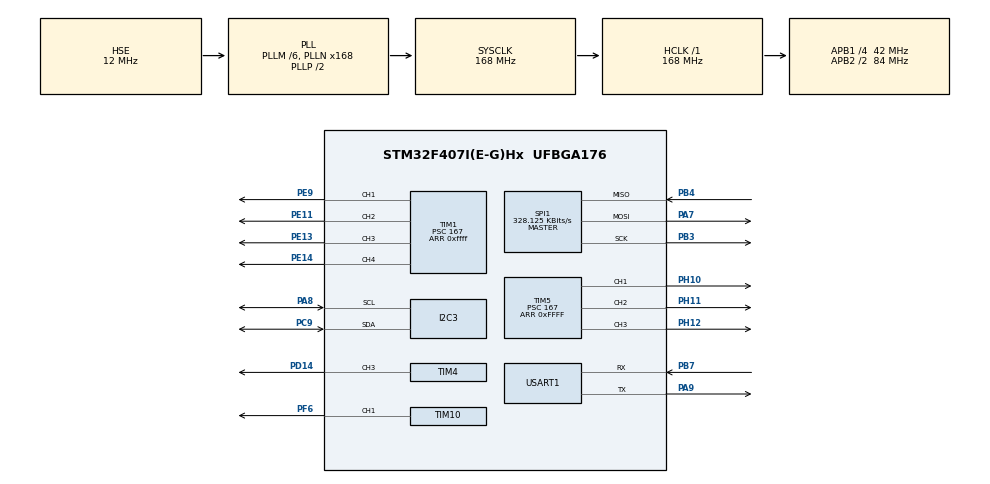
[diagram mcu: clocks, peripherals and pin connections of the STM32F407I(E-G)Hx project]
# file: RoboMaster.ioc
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Dma.Request0=USART1_TX
Dma.Request1=USART1_RX
Dma.Request2=SPI1_TX
Dma.Request3=SPI1_RX
Dma.SPI1_RX.3.Direction=DMA_PERIPH_TO_MEMORY
Dma.SPI1_RX.3.FIFOMode=DMA_FIFOMODE_DISABLE
Dma.SPI1_RX.3.Instance=DMA2_Stream0
Dma.SPI1_RX.3.MemDataAlignment=DMA_MDATAALIGN_BYTE
Dma.SPI1_RX.3.MemInc=DMA_MINC_ENABLE
Dma.SPI1_RX.3.Mode=DMA_NORMAL
Dma.SPI1_RX.3.PeriphDataAlignment=DMA_PDATAALIGN_BYTE
Dma.SPI1_RX.3.PeriphInc=DMA_PINC_DISABLE
Dma.SPI1_RX.3.Priority=DMA_PRIORITY_VERY_HIGH
Dma.SPI1_TX.2.Direction=DMA_MEMORY_TO_PERIPH
Dma.SPI1_TX.2.FIFOMode=DMA_FIFOMODE_DISABLE
Dma.SPI1_TX.2.Instance=DMA2_Stream3
Dma.SPI1_TX.2.MemDataAlignment=DMA_MDATAALIGN_BYTE
Dma.SPI1_TX.2.MemInc=DMA_MINC_ENABLE
Dma.SPI1_TX.2.Mode=DMA_NORMAL
Dma.SPI1_TX.2.PeriphDataAlignment=DMA_PDATAALIGN_BYTE
Dma.SPI1_TX.2.PeriphInc=DMA_PINC_DISABLE
Dma.SPI1_TX.2.Priority=DMA_PRIORITY_HIGH
Dma.USART1_RX.1.Direction=DMA_PERIPH_TO_MEMORY
Dma.USART1_RX.1.FIFOMode=DMA_FIFOMODE_DISABLE
Dma.USART1_RX.1.Instance=DMA2_Stream2
Dma.USART1_RX.1.MemDataAlignment=DMA_MDATAALIGN_BYTE
Dma.USART1_RX.1.MemInc=DMA_MINC_ENABLE
Dma.USART1_RX.1.Mode=DMA_NORMAL
Dma.USART1_RX.1.PeriphDataAlignment=DMA_PDATAALIGN_BYTE
Dma.USART1_RX.1.PeriphInc=DMA_PINC_DISABLE
Dma.USART1_RX.1.Priority=DMA_PRIORITY_MEDIUM
Dma.USART1_TX.0.Direction=DMA_MEMORY_TO_PERIPH
Dma.USART1_TX.0.FIFOMode=DMA_FIFOMODE_DISABLE
Dma.USART1_TX.0.Instance=DMA2_Stream7
Dma.USART1_TX.0.MemDataAlignment=DMA_MDATAALIGN_BYTE
Dma.USART1_TX.0.MemInc=DMA_MINC_ENABLE
Dma.USART1_TX.0.Mode=DMA_NORMAL
Dma.USART1_TX.0.PeriphDataAlignment=DMA_PDATAALIGN_BYTE
Dma.USART1_TX.0.PeriphInc=DMA_PINC_DISABLE
Dma.USART1_TX.0.Priority=DMA_PRIORITY_MEDIUM
FREERTOS.Tasks01=defaultTask,0,128,StartDefaultTask,Default,NULL,Dynamic,NULL,NULL
I2C3.I2C_Mode=I2C_Fast
Mcu.Family=STM32F4
Mcu.Name=STM32F407I(E-G)Hx
Mcu.Package=UFBGA176
NVIC.DMA2_Stream0_IRQn=true\:5\:0\:false\:false\:true\:true\:false\:true
NVIC.DMA2_Stream2_IRQn=true\:5\:0\:false\:false\:true\:true\:false\:true
NVIC.DMA2_Stream3_IRQn=true\:5\:0\:false\:false\:true\:true\:false\:true
NVIC.DMA2_Stream7_IRQn=true\:5\:0\:false\:false\:true\:true\:false\:true
NVIC.PriorityGroup=NVIC_PRIORITYGROUP_4
NVIC.USART1_IRQn=true\:5\:0\:false\:false\:true\:true\:true\:true
PA7.GPIO_PuPd=GPIO_PULLUP
PA7.Mode=Full_Duplex_Master
PA7.Signal=SPI1_MOSI
PA8.Mode=I2C
PA8.Signal=I2C3_SCL
PA9.Mode=Asynchronous
PA9.Signal=USART1_TX
PB3.GPIO_PuPd=GPIO_PULLUP
PB3.Mode=Full_Duplex_Master
PB3.Signal=SPI1_SCK
PB4.GPIO_PuPd=GPIO_PULLUP
PB4.Mode=Full_Duplex_Master
PB4.Signal=SPI1_MISO
PB7.Mode=Asynchronous
PB7.Signal=USART1_RX
PC9.Mode=I2C
PC9.Signal=I2C3_SDA
PD14.GPIO_PuPd=GPIO_PULLDOWN
PD14.Signal=S_TIM4_CH3
PE11.GPIO_PuPd=GPIO_PULLDOWN
PE11.Signal=S_TIM1_CH2
PE13.GPIO_PuPd=GPIO_PULLDOWN
PE13.Signal=S_TIM1_CH3
PE14.GPIO_PuPd=GPIO_PULLDOWN
PE14.Signal=S_TIM1_CH4
PE9.GPIO_PuPd=GPIO_PULLDOWN
PE9.Signal=S_TIM1_CH1
PF6.GPIO_PuPd=GPIO_PULLUP
PF6.GPIO_Speed=GPIO_SPEED_FREQ_HIGH
PF6.Signal=S_TIM10_CH1
PH0-OSC_IN.Mode=HSE-External-Oscillator
PH0-OSC_IN.Signal=RCC_OSC_IN
PH1-OSC_OUT.Mode=HSE-External-Oscillator
PH1-OSC_OUT.Signal=RCC_OSC_OUT
PH10.GPIO_PuPd=GPIO_PULLDOWN
PH10.GPIO_Speed=GPIO_SPEED_FREQ_MEDIUM
PH10.Signal=S_TIM5_CH1
PH11.GPIO_PuPd=GPIO_PULLDOWN
PH11.GPIO_Speed=GPIO_SPEED_FREQ_MEDIUM
PH11.Signal=S_TIM5_CH2
PH12.GPIO_PuPd=GPIO_PULLDOWN
PH12.GPIO_Speed=GPIO_SPEED_FREQ_MEDIUM
PH12.Signal=S_TIM5_CH3
ProjectManager.HeapSize=0x200
ProjectManager.StackSize=0x400
ProjectManager.TargetToolchain=Makefile
RCC.48MHZClocksFreq_Value=84000000
RCC.AHBFreq_Value=168000000
RCC.APB1CLKDivider=RCC_HCLK_DIV4
RCC.APB1Freq_Value=42000000
RCC.APB1TimFreq_Value=84000000
RCC.APB2CLKDivider=RCC_HCLK_DIV2
RCC.APB2Freq_Value=84000000
RCC.APB2TimFreq_Value=168000000
RCC.CortexFreq_Value=168000000
RCC.HCLKFreq_Value=168000000
RCC.HSE_VALUE=12000000
RCC.HSI_VALUE=16000000
RCC.LSE_VALUE=32768
RCC.PLLM=6
RCC.PLLN=168
RCC.PLLSourceVirtual=RCC_PLLSOURCE_HSE
RCC.SYSCLKFreq_VALUE=168000000
RCC.SYSCLKSource=RCC_SYSCLKSOURCE_PLLCLK
RCC.VCOOutputFreq_Value=336000000
SH.S_TIM10_CH1.0=TIM10_CH1,PWM Generation1 CH1
SH.S_TIM1_CH1.0=TIM1_CH1,PWM Generation1 CH1
SH.S_TIM1_CH2.0=TIM1_CH2,PWM Generation2 CH2
SH.S_TIM1_CH3.0=TIM1_CH3,PWM Generation3 CH3
SH.S_TIM1_CH4.0=TIM1_CH4,PWM Generation4 CH4
SH.S_TIM4_CH3.0=TIM4_CH3,PWM Generation3 CH3
SH.S_TIM5_CH1.0=TIM5_CH1,PWM Generation1 CH1
SH.S_TIM5_CH2.0=TIM5_CH2,PWM Generation2 CH2
SH.S_TIM5_CH3.0=TIM5_CH3,PWM Generation3 CH3
SPI1.BaudRatePrescaler=SPI_BAUDRATEPRESCALER_256
SPI1.CLKPolarity=SPI_POLARITY_HIGH
SPI1.CalculateBaudRate=328.125 KBits/s
SPI1.Direction=SPI_DIRECTION_2LINES
SPI1.Mode=SPI_MODE_MASTER
SPI1.VirtualType=VM_MASTER
TIM1.Channel-PWM\ Generation1\ CH1=TIM_CHANNEL_1
TIM1.Channel-PWM\ Generation2\ CH2=TIM_CHANNEL_2
TIM1.Channel-PWM\ Generation3\ CH3=TIM_CHANNEL_3
TIM1.Channel-PWM\ Generation4\ CH4=TIM_CHANNEL_4
TIM1.Period=0xffff
TIM1.Prescaler=167
TIM10.Channel=TIM_CHANNEL_1
TIM4.Channel-PWM\ Generation3\ CH3=TIM_CHANNEL_3
TIM4.Period=0xffff
TIM4.Prescaler=167
TIM5.Channel-PWM\ Generation1\ CH1=TIM_CHANNEL_1
TIM5.Channel-PWM\ Generation2\ CH2=TIM_CHANNEL_2
TIM5.Channel-PWM\ Generation3\ CH3=TIM_CHANNEL_3
TIM5.Period=0xFFFF
TIM5.Prescaler=167
USART1.VirtualMode=VM_ASYNC
VP_FREERTOS_VS_CMSIS_V1.Mode=CMSIS_V1
VP_TIM10_VS_ClockSourceINT.Mode=Enable_Timer
board=custom

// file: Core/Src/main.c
/* USER CODE BEGIN Header */
/**
 ******************************************************************************
 * @file           : main.c
 * @brief          : Main program body
 ******************************************************************************
 * @attention
 *
 * Copyright (c) 2022 STMicroelectronics.
 * All rights reserved.
 *
 * This software is licensed under terms that can be found in the LICENSE file
 * in the root directory of this software component.
 * If no LICENSE file comes with this software, it is provided AS-IS.
 *
 ******************************************************************************
 */
/* USER CODE END Header */
#include "main.h"
#include "cmsis_os.h"
#include "dma.h"
#include "i2c.h"
#include "spi.h"
#include "tim.h"
#include "usart.h"
#include "gpio.h"

void SystemClock_Config(void);
void MX_FREERTOS_Init(void);

int main(void)
{

    /* MCU Configuration--------------------------------------------------------*/

    /* Reset of all peripherals, Initializes the Flash interface and the Systick. */
    HAL_Init();

    /* Configure the system clock */
    SystemClock_Config();

    /* Initialize all configured peripherals */
    MX_GPIO_Init();
    MX_DMA_Init();
    MX_USART1_UART_Init();
    MX_TIM5_Init();
    MX_TIM4_Init();
    MX_TIM1_Init();
    MX_SPI1_Init();
    MX_I2C3_Init();
    MX_TIM10_Init();

    /* Call init function for freertos objects (in freertos.c) */
    MX_FREERTOS_Init();
    /* Start scheduler */
    osKernelStart();

    /* We should never get here as control is now taken by the scheduler */
    /* Infinite loop */
    /* USER CODE BEGIN WHILE */
    // while (1)
    // {
    /* USER CODE END WHILE */

    /* USER CODE BEGIN 3 */
    // }

    /* USER CODE END 3 */
}

void SystemClock_Config(void)
{
    RCC_OscInitTypeDef RCC_OscInitStruct = {0};
    RCC_ClkInitTypeDef RCC_ClkInitStruct = {0};

    /** Configure the main internal regulator output voltage
     */
    __HAL_RCC_PWR_CLK_ENABLE();
    __HAL_PWR_VOLTAGESCALING_CONFIG(PWR_REGULATOR_VOLTAGE_SCALE1);
    /** Initializes the RCC Oscillators according to the specified parameters
     * in the RCC_OscInitTypeDef structure.
     */
    RCC_OscInitStruct.OscillatorType = RCC_OSCILLATORTYPE_HSE;
    RCC_OscInitStruct.HSEState = RCC_HSE_ON;
    RCC_OscInitStruct.PLL.PLLState = RCC_PLL_ON;
    RCC_OscInitStruct.PLL.PLLSource = RCC_PLLSOURCE_HSE;
    RCC_OscInitStruct.PLL.PLLM = 6;
    RCC_OscInitStruct.PLL.PLLN = 168;
    RCC_OscInitStruct.PLL.PLLP = RCC_PLLP_DIV2;
    RCC_OscInitStruct.PLL.PLLQ = 4;
    if (HAL_RCC_OscConfig(&RCC_OscInitStruct) != HAL_OK)
    {
        Error_Handler();
    }
    /** Initializes the CPU, AHB and APB buses clocks
     */
    RCC_ClkInitStruct.ClockType = RCC_CLOCKTYPE_HCLK | RCC_CLOCKTYPE_SYSCLK | RCC_CLOCKTYPE_PCLK1 | RCC_CLOCKTYPE_PCLK2;
    RCC_ClkInitStruct.SYSCLKSource = RCC_SYSCLKSOURCE_PLLCLK;
    RCC_ClkInitStruct.AHBCLKDivider = RCC_SYSCLK_DIV1;
    RCC_ClkInitStruct.APB1CLKDivider = RCC_HCLK_DIV4;
    RCC_ClkInitStruct.APB2CLKDivider = RCC_HCLK_DIV2;

    if (HAL_RCC_ClockConfig(&RCC_ClkInitStruct, FLASH_LATENCY_5) != HAL_OK)
    {
        Error_Handler();
    }
}

void Error_Handler(void)
{
    __disable_irq();
    while (1)
    {
    }
}

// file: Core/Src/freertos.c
/* USER CODE BEGIN Header */
/**
 ******************************************************************************
 * File Name          : freertos.c
 * Description        : Code for freertos applications
 ******************************************************************************
 * @attention
 *
 * Copyright (c) 2022 STMicroelectronics.
 * All rights reserved.
 *
 * This software is licensed under terms that can be found in the LICENSE file
 * in the root directory of this software component.
 * If no LICENSE file comes with this software, it is provided AS-IS.
 *
 ******************************************************************************
 */
/* USER CODE END Header */

#include "FreeRTOS.h"
#include "task.h"
#include "main.h"
#include "cmsis_os.h"

#include "global.h"

osThreadId defaultTaskHandle;
osThreadId triggerTaskHandle;

void StartDefaultTask(void const * argument);
void StartTriggerTask(void const * argument);

void MX_FREERTOS_Init(void); /* (MISRA C 2004 rule 8.1) */

/* GetIdleTaskMemory prototype (linked to static allocation support) */
void vApplicationGetIdleTaskMemory( StaticTask_t **ppxIdleTaskTCBBuffer, StackType_t **ppxIdleTaskStackBuffer, uint32_t *pulIdleTaskStackSize );

/* USER CODE BEGIN GET_IDLE_TASK_MEMORY */
static StaticTask_t xIdleTaskTCBBuffer;
static StackType_t xIdleStack[configMINIMAL_STACK_SIZE];

void vApplicationGetIdleTaskMemory(StaticTask_t **ppxIdleTaskTCBBuffer, StackType_t **ppxIdleTaskStackBuffer, uint32_t *pulIdleTaskStackSize)
{
    *ppxIdleTaskTCBBuffer = &xIdleTaskTCBBuffer;
    *ppxIdleTaskStackBuffer = &xIdleStack[0];
    *pulIdleTaskStackSize = configMINIMAL_STACK_SIZE;
    /* place for user code */
}
/* USER CODE END GET_IDLE_TASK_MEMORY */

void MX_FREERTOS_Init(void) {

  /* Create the thread(s) */
  /* definition and creation of defaultTask */
  osThreadDef(defaultTask, StartDefaultTask, osPriorityRealtime, 0, 1024);
  defaultTaskHandle = osThreadCreate(osThread(defaultTask), NULL);

  osThreadDef(triggerTask, StartTriggerTask, osPriorityNormal, 0, 256);
  triggerTaskHandle = osThreadCreate(osThread(triggerTask), NULL);

}

void StartDefaultTask(void const * argument)
{
  /* USER CODE BEGIN StartDefaultTask */
    /* Infinite loop */
    //   for(;;)
    //   {
    //     osDelay(1);
    //   }

    main_task_init();
    MAIN_TASK.run();
  /* USER CODE END StartDefaultTask */
}

void StartTriggerTask(void const * argument)
{
  /* USER CODE BEGIN test_task */
  /* Infinite loop */
  for(;;)
  {
    osDelay(1000);
    xTaskNotifyGive(defaultTaskHandle);
  }
  /* USER CODE END test_task */
}
